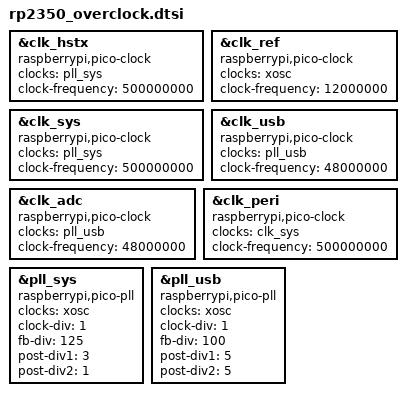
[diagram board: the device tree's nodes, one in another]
/* 400 MHz, voltage 1.35v */
// &clk_hstx {
// 	compatible = "raspberrypi,pico-clock";
// 	clocks = <&pll_sys>;
// 	clock-names = "pll_sys";
// 	clock-frequency = <400000000>;
// 	#clock-cells = <0>;
// };
//
// &clk_ref {
// 	compatible = "raspberrypi,pico-clock";
// 	clocks = <&xosc>;
// 	clock-names = "xosc";
// 	clock-frequency = <12000000>;
// 	#clock-cells = <0>;
// };
//
// &clk_sys {
// 	compatible = "raspberrypi,pico-clock";
// 	clocks = <&pll_sys>;
// 	clock-names = "pll_sys";
// 	clock-frequency = <400000000>;
// 	#clock-cells = <0>;
// };
//
// &clk_usb {
// 	compatible = "raspberrypi,pico-clock";
// 	clocks = <&pll_usb>;
// 	clock-names = "pll_usb";
// 	clock-frequency = <48000000>;
// 	#clock-cells = <0>;
// };
//
// &clk_adc {
// 	compatible = "raspberrypi,pico-clock";
// 	clocks = <&pll_usb>;
// 	clock-names = "pll_usb";
// 	clock-frequency = <48000000>;
// 	#clock-cells = <0>;
// };
//
// &clk_peri {
// 	compatible = "raspberrypi,pico-clock";
// 	clocks = <&clk_sys>;
// 	clock-names = "clk_sys";
// 	clock-frequency = <400000000>;
// 	#clock-cells = <0>;
// };
//
// &pll_sys {
// 	compatible = "raspberrypi,pico-pll";
// 	clocks = <&xosc>;
// 	clock-names = "xosc";
// 	clock-div = <1>;
// 	fb-div = <100>;
// 	post-div1 = <3>;
// 	post-div2 = <1>;
// 	#clock-cells = <0>;
// };
//
// &pll_usb {
// 	compatible = "raspberrypi,pico-pll";
// 	clocks = <&xosc>;
// 	clock-names = "xosc";
// 	clock-div = <1>;
// 	fb-div = <100>;
// 	post-div1 = <5>;
// 	post-div2 = <5>;
// 	#clock-cells = <0>;
// };

/* 500 MHz, voltage 1.6v */
&clk_hstx {
	compatible = "raspberrypi,pico-clock";
	clocks = <&pll_sys>;
	clock-names = "pll_sys";
	clock-frequency = <500000000>;
	#clock-cells = <0>;
};

&clk_ref {
	compatible = "raspberrypi,pico-clock";
	clocks = <&xosc>;
	clock-names = "xosc";
	clock-frequency = <12000000>;
	#clock-cells = <0>;
};

&clk_sys {
	compatible = "raspberrypi,pico-clock";
	clocks = <&pll_sys>;
	clock-names = "pll_sys";
	clock-frequency = <500000000>;
	#clock-cells = <0>;
};

&clk_usb {
	compatible = "raspberrypi,pico-clock";
	clocks = <&pll_usb>;
	clock-names = "pll_usb";
	clock-frequency = <48000000>;
	#clock-cells = <0>;
};

&clk_adc {
	compatible = "raspberrypi,pico-clock";
	clocks = <&pll_usb>;
	clock-names = "pll_usb";
	clock-frequency = <48000000>;
	#clock-cells = <0>;
};

&clk_peri {
	compatible = "raspberrypi,pico-clock";
	clocks = <&clk_sys>;
	clock-names = "clk_sys";
	clock-frequency = <500000000>;
	#clock-cells = <0>;
};

&pll_sys {
	compatible = "raspberrypi,pico-pll";
	clocks = <&xosc>;
	clock-names = "xosc";
	clock-div = <1>;
	fb-div = <125>;
	post-div1 = <3>;
	post-div2 = <1>;
	#clock-cells = <0>;
};

&pll_usb {
	compatible = "raspberrypi,pico-pll";
	clocks = <&xosc>;
	clock-names = "xosc";
	clock-div = <1>;
	fb-div = <100>;
	post-div1 = <5>;
	post-div2 = <5>;
	#clock-cells = <0>;
};
